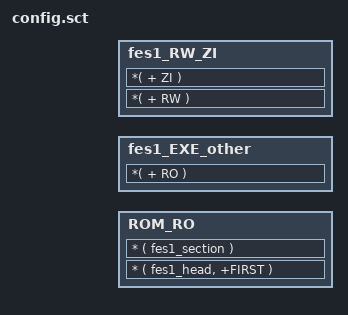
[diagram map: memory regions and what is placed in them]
#! armcc -E
;/*
; * (C) Copyright 2012
; *     wangflord@allwinnertech.com
; *
; *
; * This program is free software; you can redistribute it and/or
; * modify it under the terms of the GNU General Public License as
; * published by the Free Software Foundation; either version 2 of
; * the License, or (at your option) any later version.
; *
; * This program is distributed in the hope that it will be useful,
; * but WITHOUT ANY WARRANTY; without even the implied warranty of
; * MERCHANTABILITY or FITNESS FOR A PARTICULAR PURPOSE.  See the
; * GNU General Public License for more details.
; *
; * You should have received a copy of the GNU General Public License
; * along with this program;
; *
; */

FES1_LOAD RUN_ADDR
{
    ROM_RO +0x0000
    {
    	* ( fes1_head, +FIRST )
        * ( fes1_section )
    }

    fes1_EXE_other +0
	{
		*( + RO )
	}

	fes1_RW_ZI  +0
	{
		*( + RW )
		*( + ZI )
	}
}

